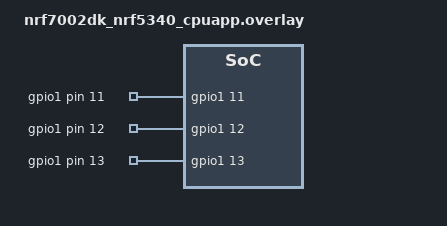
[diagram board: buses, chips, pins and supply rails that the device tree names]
// To get started, press Ctrl+Space to bring up the completion menu and view the available nodes.

// You can also use the buttons in the sidebar to perform actions on nodes.
// Actions currently available include:

// * Enabling / disabling the node
// * Adding the bus to a bus
// * Removing the node
// * Connecting ADC channels

// For more help, browse the DeviceTree documentation at https://docs.zephyrproject.org/latest/guides/dts/index.html
// You can also visit the nRF DeviceTree extension documentation at https://nrfconnect.github.io/vscode-nrf-connect/devicetree/nrfdevicetree.html
/ {
    gpiocustom {
        compatible = "gpio-keys";
        gpio11: gpio11 {
            gpios = <&gpio1 11 GPIO_ACTIVE_HIGH>;
            label = "gpio1 pin 11";
        };
        gpio12: gpio12 {
            gpios = <&gpio1 12 GPIO_ACTIVE_HIGH>;
            label = "gpio1 pin 12";
        };
        gpio13: gpio13 {
            gpios = <&gpio1 13 GPIO_ACTIVE_HIGH>;
            label = "gpio1 pin 13";
        };
    };
    aliases {
        gpio11 = &gpio11;
        gpio12 = &gpio12;
        gpio13 = &gpio13;
    };
};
